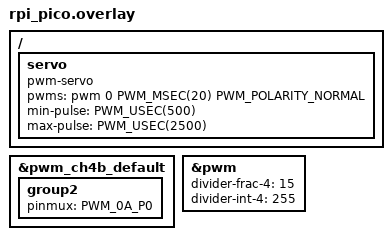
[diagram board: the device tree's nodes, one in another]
/* SPDX-License-Identifier: Apache-2.0 */

/ {
    servo: servo {
        compatible = "pwm-servo";
        pwms = <&pwm 0 PWM_MSEC(20) PWM_POLARITY_NORMAL>;
        min-pulse = <PWM_USEC(500)>;
                max-pulse = <PWM_USEC(2500)>;
    };
};

&pwm_ch4b_default {
    group2 {
        pinmux = <PWM_0A_P0>;
    };
};

&pwm {
    status = "okay";
    divider-frac-4 = <15>;
    divider-int-4 = <255>;
};
